# STM32WL55xx register map
File version: 1.0
Registers are 32-bit, read-write, reset 0x0 unless marked. A register's access mark holds for its fields unless they carry their own. Offsets are from the block's base; [hi:lo] are bit positions; {n}, {i} and the like mark numbered series.

## RSSLIB_PFUNC — RSSLib function pointer structure
Base 0x1FFF3A00
0x00 CloseExitHDP

## WWDG — Window WATCHDOG
Base 0x40002C00
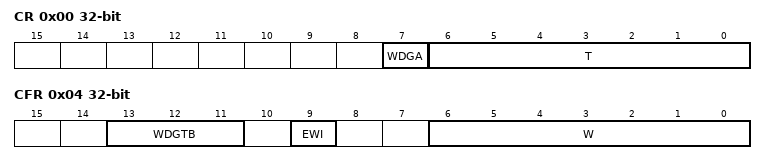
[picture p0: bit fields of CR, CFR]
0x00 CR — WWDG Control register
  [7] WDGA — Activation bit
  [6:0] T — T[6:0] bits (7-Bit counter (MSB to LSB))
0x04 CFR — WWDG Configuration register
  [13:11] WDGTB — WDGTB[2:0] bits (Timer Base)
    0=PRESCALER_1 (WWDG counter clock = (PCLK1/4096)/1); 1=PRESCALER_2 (WWDG counter clock = (PCLK1/4096)/2); 2=PRESCALER_4 (WWDG counter clock = (PCLK1/4096)/4); 3=PRESCALER_8 (WWDG counter clock = (PCLK1/4096)/8); 4=PRESCALER_16 (WWDG counter clock = (PCLK1/4096)/16); 5=PRESCALER_32 (WWDG counter clock = (PCLK1/4096)/32); 6=PRESCALER_64 (WWDG counter clock = (PCLK1/4096)/64); 7=PRESCALER_128 (WWDG counter clock = (PCLK1/4096)/128)
  [9] EWI — Early Wakeup Interrupt
  [6:0] W — W[6:0] bits (7-bit window value)
0x08 SR — WWDG Status register
  [0] EWIF — Early Wakeup Interrupt Flag

## IWDG — Independent WATCHDOG
Base 0x40003000
0x00 KR — IWDG Key register
  [15:0] KEY — Key value (write only, read 0000h)
0x04 PR — IWDG Prescaler register
  [2:0] PR — PR[2:0] (Prescaler divider)
0x08 RLR — IWDG Reload register
  [11:0] RL — Watchdog counter reload value
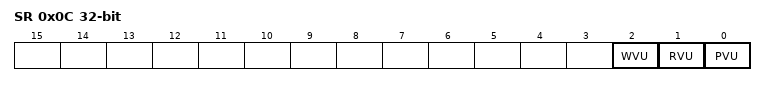
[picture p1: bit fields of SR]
0x0C SR — IWDG Status register
  [2] WVU — Watchdog counter window value update
  [1] RVU — Watchdog counter reload value update
  [0] PVU — Watchdog prescaler value update
0x10 WINR — IWDG Window register
  [11:0] WIN — Watchdog counter window value

## DAC — Digital to Analog Converter
Base 0x40007400
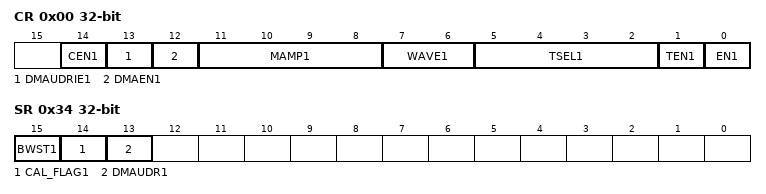
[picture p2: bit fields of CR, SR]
0x00 CR — DAC control register
  [14] CEN1 — DAC channel 1 calibration enable >
  [13] DMAUDRIE1 — DAC channel 1 DMA underrun interrupt enable >
  [12] DMAEN1 — DAC channel1 DMA enable
  [11:8] MAMP1 — MAMP1[3:0] (DAC channel1 Mask/Amplitude selector)
  [7:6] WAVE1 — WAVE1[1:0] (DAC channel1 noise/triangle wave generation enable)
  [5:2] TSEL1 — TSEL1[3:0] (DAC channel1 Trigger selection)
  [1] TEN1 — DAC channel1 Trigger enable
  [0] EN1 — DAC channel1 enable
0x04 SWTRIGR — DAC software trigger register
  [0] SWTRIG1 — DAC channel1 software trigger
0x08 DHR12R1 — DAC channel1 12-bit right-aligned data holding register
  [11:0] DACC1DHR — DAC channel1 12-bit Right aligned data
0x0C DHR12L1 — DAC channel1 12-bit left aligned data holding register
  [15:4] DACC1DHR — DAC channel1 12-bit Left aligned data
0x10 DHR8R1 — DAC channel1 8-bit right aligned data holding register
  [7:0] DACC1DHR — DAC channel1 8-bit Right aligned data
0x20 DHR12RD — Dual DAC 12-bit right-aligned data holding register
  [11:0] DACC1DHR — DAC channel1 12-bit Right aligned data
0x24 DHR12LD — DUAL DAC 12-bit left aligned data holding register
  [15:4] DACC1DHR — DAC channel1 12-bit Left aligned data
0x28 DHR8RD — DUAL DAC 8-bit right aligned data holding register
  [7:0] DACC1DHR — DAC channel1 8-bit Right aligned data
0x2C DOR1 — DAC channel1 data output register
  [11:0] DACC1DOR — DAC channel1 data output
0x34 SR — DAC status register
  [15] BWST1 — DAC channel1 busy writing sample time flag
  [14] CAL_FLAG1 — DAC channel1 calibration offset status
  [13] DMAUDR1 — DAC channel1 DMA underrun flag
0x38 CCR — DAC calibration control register
  [4:0] OTRIM1 — DAC channel1 offset trimming value
0x3C MCR — DAC mode control register
  [2:0] MODE1 — MODE1[2:0] (DAC channel1 mode)
0x40 SHSR1 — DAC Sample and Hold sample time register 1
  [9:0] TSAMPLE1 — DAC channel1 sample time
0x48 SHHR — DAC Sample and Hold hold time register
  [9:0] THOLD1 — DAC channel1 hold time
0x4C SHRR — DAC Sample and Hold refresh time register
  [7:0] TREFRESH1 — DAC channel1 refresh time

## TAMP — Tamper and backup registers
Base 0x4000B000
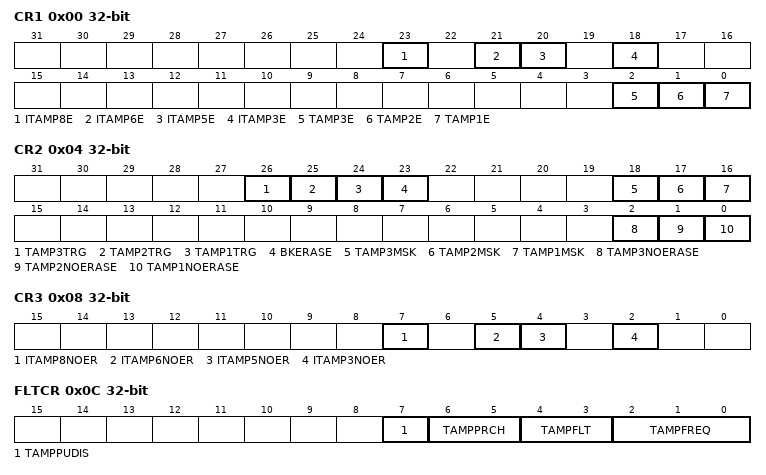
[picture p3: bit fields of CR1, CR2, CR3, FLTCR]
0x00 CR1 — TAMP configuration register 1
  [23] ITAMP8E, [21] ITAMP6E, [20] ITAMP5E, [18] ITAMP3E, [2] TAMP3E, [1] TAMP2E, [0] TAMP1E
0x04 CR2 — TAMP configuration register 2
  [26] TAMP3TRG, [25] TAMP2TRG, [24] TAMP1TRG, [23] BKERASE, [18] TAMP3MSK, [17] TAMP2MSK, [16] TAMP1MSK, [2] TAMP3NOERASE, [1] TAMP2NOERASE, [0] TAMP1NOERASE
0x08 CR3 — TAMP configuration register 3
  [7] ITAMP8NOER, [5] ITAMP6NOER, [4] ITAMP5NOER, [2] ITAMP3NOER
0x0C FLTCR — TAMP filter control register
  [7] TAMPPUDIS
  [6:5] TAMPPRCH
    0=DURATION_1RTCCLK (Tamper pins are pre-charged before sampling during 1 RTCCLK cycle); 1=DURATION_2RTCCLK (Tamper pins are pre-charged before sampling during 2 RTCCLK cycles); 2=DURATION_4RTCCLK (Tamper pins are pre-charged before sampling during 4 RTCCLK cycles); 3=DURATION_8RTCCLK (Tamper pins are pre-charged before sampling during 8 RTCCLK cycles)
  [4:3] TAMPFLT
    0=DISABLE (Tamper filter is disabled); 1=FILTER_2SAMPLE (Tamper is activated after 2 consecutive samples at the active level); 2=FILTER_4SAMPLE (Tamper is activated after 4 consecutive samples at the active level); 3=FILTER_8SAMPLE (Tamper is activated after 8 consecutive samples at the active level.)
  [2:0] TAMPFREQ
    0=SAMPLFREQDIV_32768 (Each of the tamper inputs are sampled with a frequency = RTCCLK / 32768); 1=SAMPLFREQDIV_16384 (Each of the tamper inputs are sampled with a frequency = RTCCLK / 16384); 2=SAMPLFREQDIV_8192 (Each of the tamper inputs are sampled with a frequency = RTCCLK / 8192); 3=SAMPLFREQDIV_4096 (Each of the tamper inputs are sampled with a frequency = RTCCLK / 4096); 4=SAMPLFREQDIV_2048 (Each of the tamper inputs are sampled with a frequency = RTCCLK / 2048); 5=SAMPLFREQDIV_1024 (Each of the tamper inputs are sampled with a frequency = RTCCLK / 1024); 6=SAMPLFREQDIV_512 (Each of the tamper inputs are sampled with a frequency = RTCCLK / 512); 7=SAMPLFREQDIV_256 (Each of the tamper inputs are sampled with a frequency = RTCCLK / 256)
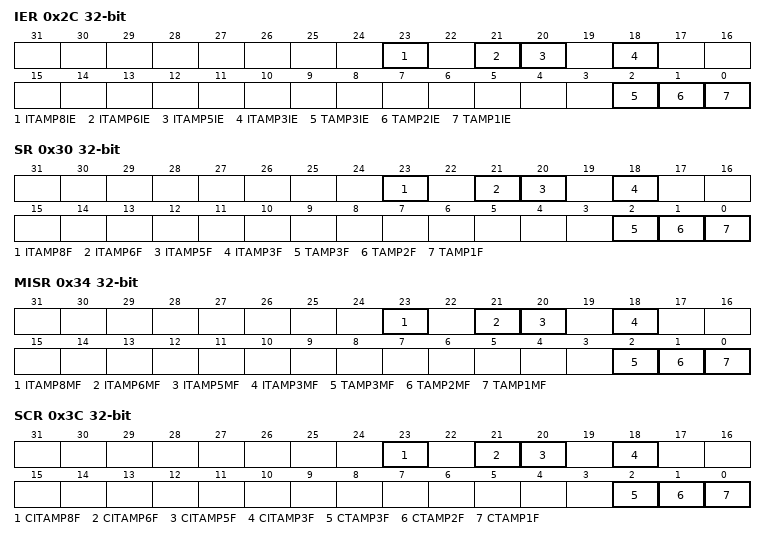
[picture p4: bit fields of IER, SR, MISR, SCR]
0x2C IER — TAMP interrupt enable register
  [23] ITAMP8IE, [21] ITAMP6IE, [20] ITAMP5IE, [18] ITAMP3IE, [2] TAMP3IE, [1] TAMP2IE, [0] TAMP1IE
0x30 SR — TAMP status register
  [23] ITAMP8F, [21] ITAMP6F, [20] ITAMP5F, [18] ITAMP3F, [2] TAMP3F, [1] TAMP2F, [0] TAMP1F
0x34 MISR — TAMP masked interrupt status register
  [23] ITAMP8MF, [21] ITAMP6MF, [20] ITAMP5MF, [18] ITAMP3MF, [2] TAMP3MF, [1] TAMP2MF, [0] TAMP1MF
0x3C SCR — TAMP status clear register
  [23] CITAMP8F, [21] CITAMP6F, [20] CITAMP5F, [18] CITAMP3F, [2] CTAMP3F, [1] CTAMP2F, [0] CTAMP1F
0x40 COUNTR — TAMP monotonic counter register
{0x100+4i} BKP{i}R (i=0..19) — TAMP backup register {i}
